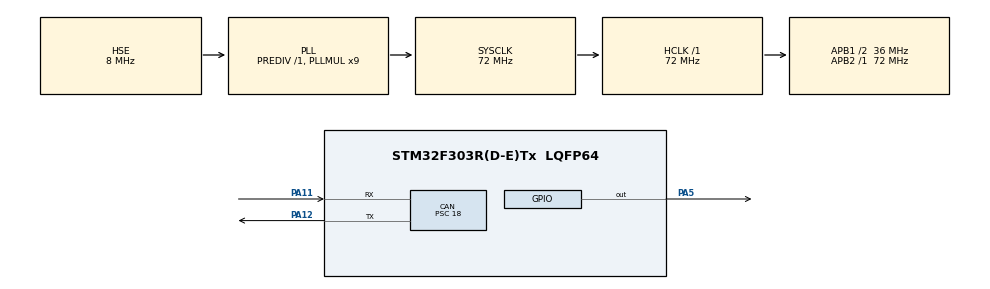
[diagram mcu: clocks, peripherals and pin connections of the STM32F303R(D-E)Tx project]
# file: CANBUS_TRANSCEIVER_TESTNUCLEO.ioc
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CAN.BS1=CAN_BS1_2TQ
CAN.BS2=CAN_BS2_2TQ
CAN.CalculateBaudRate=400000
CAN.CalculateTimeBit=2500
CAN.CalculateTimeQuantum=500.0
CAN.Prescaler=18
Mcu.Family=STM32F3
Mcu.Name=STM32F303R(D-E)Tx
Mcu.Package=LQFP64
NVIC.CAN_RX1_IRQn=true\:0\:0\:false\:false\:true\:true\:true\:true
NVIC.PriorityGroup=NVIC_PRIORITYGROUP_4
PA11.Mode=CAN_Activate
PA11.Signal=CAN_RX
PA12.Mode=CAN_Activate
PA12.Signal=CAN_TX
PA13.Mode=Serial_Wire
PA13.Signal=SYS_JTMS-SWDIO
PA14.Mode=Serial_Wire
PA14.Signal=SYS_JTCK-SWCLK
PA5.Signal=GPIO_Output
PF0-OSC_IN.Mode=HSE-External-Oscillator
PF0-OSC_IN.Signal=RCC_OSC_IN
PF1-OSC_OUT.Mode=HSE-External-Oscillator
PF1-OSC_OUT.Signal=RCC_OSC_OUT
ProjectManager.HeapSize=0x200
ProjectManager.StackSize=0x400
ProjectManager.TargetToolchain=STM32CubeIDE
RCC.AHBFreq_Value=72000000
RCC.APB1CLKDivider=RCC_HCLK_DIV2
RCC.APB1Freq_Value=36000000
RCC.APB1TimFreq_Value=72000000
RCC.APB2Freq_Value=72000000
RCC.APB2TimFreq_Value=72000000
RCC.CortexFreq_Value=72000000
RCC.HCLKFreq_Value=72000000
RCC.HSE_VALUE=8000000
RCC.HSI_VALUE=8000000
RCC.LSE_VALUE=32768
RCC.PLLMUL=RCC_PLL_MUL9
RCC.PLLSourceVirtual=RCC_PLLSOURCE_HSE
RCC.SYSCLKFreq_VALUE=72000000
RCC.SYSCLKSourceVirtual=RCC_SYSCLKSOURCE_PLLCLK
RCC.USBFreq_Value=72000000
board=custom

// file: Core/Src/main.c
/* USER CODE BEGIN Header */
/**
  ******************************************************************************
  * @file           : main.c
  * @brief          : Main program body
  ******************************************************************************
  * @attention
  *
  * Copyright (c) 2024 STMicroelectronics.
  * All rights reserved.
  *
  * This software is licensed under terms that can be found in the LICENSE file
  * in the root directory of this software component.
  * If no LICENSE file comes with this software, it is provided AS-IS.
  *
  ******************************************************************************
  */
/* USER CODE END Header */
#include "main.h"

/* USER CODE BEGIN Includes */

CAN_RxHeaderTypeDef RxHeader;
uint8_t RxData[8];
uint8_t control;

/* USER CODE END Includes */

CAN_HandleTypeDef hcan;

void SystemClock_Config(void);
static void MX_GPIO_Init(void);
static void MX_CAN_Init(void);

/* USER CODE BEGIN 0 */

void HAL_CAN_RxFifo1MsgPendingCallback(CAN_HandleTypeDef *hcan)
{
	HAL_CAN_GetRxMessage(hcan, CAN_RX_FIFO1, &RxHeader, RxData);

	if(RxHeader.StdId == 0x446)
	{
		control = 1;
		HAL_GPIO_WritePin(GPIOA,GPIO_PIN_5, GPIO_PIN_SET);
	}
}

/* USER CODE END 0 */

int main(void)
{

  /* MCU Configuration--------------------------------------------------------*/

  /* Reset of all peripherals, Initializes the Flash interface and the Systick. */
  HAL_Init();

  /* Configure the system clock */
  SystemClock_Config();

  /* Initialize all configured peripherals */
  MX_GPIO_Init();
  MX_CAN_Init();
  /* USER CODE BEGIN 2 */

  HAL_CAN_ActivateNotification(&hcan, CAN_IT_RX_FIFO1_MSG_PENDING);

  /* USER CODE END 2 */

  /* Infinite loop */
  while (1)
  {

  }
}

void SystemClock_Config(void)
{
  RCC_OscInitTypeDef RCC_OscInitStruct = {0};
  RCC_ClkInitTypeDef RCC_ClkInitStruct = {0};

  /** Initializes the RCC Oscillators according to the specified parameters
  * in the RCC_OscInitTypeDef structure.
  */
  RCC_OscInitStruct.OscillatorType = RCC_OSCILLATORTYPE_HSE;
  RCC_OscInitStruct.HSEState = RCC_HSE_ON;
  RCC_OscInitStruct.HSIState = RCC_HSI_ON;
  RCC_OscInitStruct.PLL.PLLState = RCC_PLL_ON;
  RCC_OscInitStruct.PLL.PLLSource = RCC_PLLSOURCE_HSE;
  RCC_OscInitStruct.PLL.PLLMUL = RCC_PLL_MUL9;
  RCC_OscInitStruct.PLL.PREDIV = RCC_PREDIV_DIV1;
  if (HAL_RCC_OscConfig(&RCC_OscInitStruct) != HAL_OK)
  {
    Error_Handler();
  }

  /** Initializes the CPU, AHB and APB buses clocks
  */
  RCC_ClkInitStruct.ClockType = RCC_CLOCKTYPE_HCLK|RCC_CLOCKTYPE_SYSCLK
                              |RCC_CLOCKTYPE_PCLK1|RCC_CLOCKTYPE_PCLK2;
  RCC_ClkInitStruct.SYSCLKSource = RCC_SYSCLKSOURCE_PLLCLK;
  RCC_ClkInitStruct.AHBCLKDivider = RCC_SYSCLK_DIV1;
  RCC_ClkInitStruct.APB1CLKDivider = RCC_HCLK_DIV2;
  RCC_ClkInitStruct.APB2CLKDivider = RCC_HCLK_DIV1;

  if (HAL_RCC_ClockConfig(&RCC_ClkInitStruct, FLASH_LATENCY_2) != HAL_OK)
  {
    Error_Handler();
  }
}

static void MX_CAN_Init(void)
{

  hcan.Instance = CAN;
  hcan.Init.Prescaler = 18;
  hcan.Init.Mode = CAN_MODE_NORMAL;
  hcan.Init.SyncJumpWidth = CAN_SJW_1TQ;
  hcan.Init.TimeSeg1 = CAN_BS1_2TQ;
  hcan.Init.TimeSeg2 = CAN_BS2_2TQ;
  hcan.Init.TimeTriggeredMode = DISABLE;
  hcan.Init.AutoBusOff = DISABLE;
  hcan.Init.AutoWakeUp = DISABLE;
  hcan.Init.AutoRetransmission = DISABLE;
  hcan.Init.ReceiveFifoLocked = DISABLE;
  hcan.Init.TransmitFifoPriority = DISABLE;
  if (HAL_CAN_Init(&hcan) != HAL_OK)
  {
    Error_Handler();
  }
  /* USER CODE BEGIN CAN_Init 2 */

  CAN_FilterTypeDef FilterHandler;

  FilterHandler.FilterActivation = CAN_FILTER_ENABLE;
  FilterHandler.FilterBank = 13;
  FilterHandler.FilterFIFOAssignment = CAN_FILTER_FIFO1;
  FilterHandler.FilterIdHigh = 0x446 << 5;
  FilterHandler.FilterIdLow = 0;
  FilterHandler.FilterMaskIdHigh = 0x446 << 5;
  FilterHandler.FilterMaskIdLow = 0;
  FilterHandler.FilterMode = CAN_FILTERMODE_IDMASK;
  FilterHandler.FilterScale = CAN_FILTERSCALE_32BIT;

  HAL_CAN_ConfigFilter(&hcan, &FilterHandler);

  /* USER CODE END CAN_Init 2 */

}

static void MX_GPIO_Init(void)
{
  GPIO_InitTypeDef GPIO_InitStruct = {0};

  /* GPIO Ports Clock Enable */
  __HAL_RCC_GPIOF_CLK_ENABLE();
  __HAL_RCC_GPIOA_CLK_ENABLE();

  /*Configure GPIO pin Output Level */
  HAL_GPIO_WritePin(GPIOA, GPIO_PIN_5, GPIO_PIN_RESET);

  /*Configure GPIO pin : PA5 */
  GPIO_InitStruct.Pin = GPIO_PIN_5;
  GPIO_InitStruct.Mode = GPIO_MODE_OUTPUT_PP;
  GPIO_InitStruct.Pull = GPIO_NOPULL;
  GPIO_InitStruct.Speed = GPIO_SPEED_FREQ_LOW;
  HAL_GPIO_Init(GPIOA, &GPIO_InitStruct);

}

void Error_Handler(void)
{
  __disable_irq();
  while (1)
  {
  }
}
